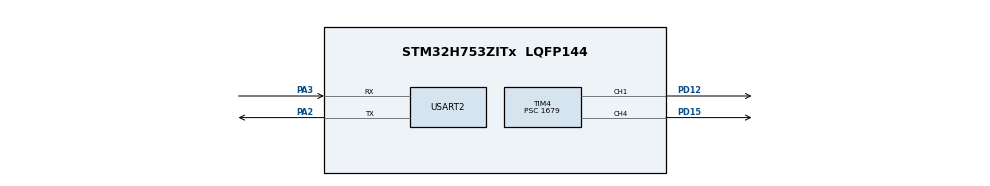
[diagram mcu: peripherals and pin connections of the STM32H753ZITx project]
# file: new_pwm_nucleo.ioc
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CORTEX_M7.CPU_DCache=Disabled
CORTEX_M7.CPU_ICache=Disabled
CORTEX_M7.MPU_Control=__NULL
CORTEX_M7.default_mode_Activation=1
Mcu.Family=STM32H7
Mcu.Name=STM32H753ZITx
Mcu.Package=LQFP144
NUCLEO-H753ZI.BUTTON=1
NUCLEO-H753ZI.Bsp_Common_DEMO=true
NUCLEO-H753ZI.LD1=true
NUCLEO-H753ZI.LD2=true
NUCLEO-H753ZI.LD3=true
NUCLEO-H753ZI.VCP=true
NVIC.EXTI15_10_IRQn=true\:0\:0\:false\:false\:true\:false\:true\:true
NVIC.PriorityGroup=NVIC_PRIORITYGROUP_4
PA2.Mode=Asynchronous
PA2.Signal=USART2_TX
PA3.Mode=Asynchronous
PA3.Signal=USART2_RX
PC14-OSC32_IN\ (OSC32_IN).Signal=RCC_OSC32_IN
PC15-OSC32_OUT\ (OSC32_OUT).Signal=RCC_OSC32_OUT
PD12.Signal=S_TIM4_CH1
PD15.Signal=S_TIM4_CH4
PD8.Signal=USART3_TX
PD9.Signal=USART3_RX
PH0-OSC_IN\ (PH0).Signal=RCC_OSC_IN
PH1-OSC_OUT\ (PH1).Signal=RCC_OSC_OUT
ProjectManager.HeapSize=0x200
ProjectManager.StackSize=0x400
ProjectManager.TargetToolchain=STM32CubeIDE
RCC.ADCFreq_Value=129000000
RCC.APB1Freq_Value=64000000
RCC.APB2Freq_Value=64000000
RCC.APB3Freq_Value=64000000
RCC.APB4Freq_Value=64000000
RCC.CortexFreq_Value=64000000
RCC.DIVM1=1
RCC.DIVN1=24
RCC.DIVQ1=4
RCC.HCLKFreq_Value=64000000
RCC.HSE_VALUE=8000000
RCC.PLLFRACN=0
RCC.PWR_Regulator_Voltage_Scale=PWR_REGULATOR_VOLTAGE_SCALE2
RCC.SYSCLKFreq_VALUE=64000000
RCC.USBFreq_Value=384000000
SH.S_TIM4_CH1.0=TIM4_CH1,PWM Generation1 CH1
SH.S_TIM4_CH4.0=TIM4_CH4,PWM Generation4 CH4
TIM4.AutoReloadPreload=TIM_AUTORELOAD_PRELOAD_ENABLE
TIM4.Channel-PWM\ Generation1\ CH1=TIM_CHANNEL_1
TIM4.Channel-PWM\ Generation4\ CH4=TIM_CHANNEL_4
TIM4.Period=999
TIM4.Prescaler=1679
USART2.VirtualMode-Asynchronous=VM_ASYNC
VP_MEMORYMAP_VS_MEMORYMAP.Mode=CurAppReg
VP_NUCLEO-H753ZI_VS_BSP_COMMON.Mode=COMMON
board=NUCLEO-H753ZI

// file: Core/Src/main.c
/* USER CODE BEGIN Header */
/**
  ******************************************************************************
  * @file           : main.c
  * @brief          : PWM Fade + UART Percentage Print (STM32F407G-DISC1)
  ******************************************************************************
  */
/* USER CODE END Header */

#include "main.h"
#include <stdio.h>
#include <string.h>

TIM_HandleTypeDef htim4;
UART_HandleTypeDef huart2;

void SystemClock_Config(void);
static void MX_GPIO_Init(void);
static void MX_TIM4_Init(void);
static void MX_USART2_UART_Init(void);

/* USER CODE BEGIN 0 */
static void UART_SendString(const char *s)
{
  HAL_UART_Transmit(&huart2, (uint8_t*)s, (uint16_t)strlen(s), HAL_MAX_DELAY);
}
/* USER CODE END 0 */

int main(void)
{
  HAL_Init();
  SystemClock_Config();

  MX_GPIO_Init();
  MX_TIM4_Init();
  MX_USART2_UART_Init();

  HAL_TIM_PWM_Start(&htim4, TIM_CHANNEL_1);

  UART_SendString("\r\n=== PWM Fade Started ===\r\n");

  uint32_t period = htim4.Init.Period;
  int last_printed_percent = -1;

  while (1)
  {
    /* Fade in */
    for (uint32_t duty = 0; duty <= period; duty += 2)
    {
      __HAL_TIM_SET_COMPARE(&htim4, TIM_CHANNEL_1, duty);

      int percent = (int)((duty * 100UL) / period);

      /* Print only each 5% change (reduce spam) */
      if (percent % 5 == 0 && percent != last_printed_percent)
      {
        char msg[64];
        snprintf(msg, sizeof(msg), "LED Brightness: %d%%\r\n", percent);
        UART_SendString(msg);
        last_printed_percent = percent;
      }

      HAL_Delay(5);
    }

    /* Fade out */
    for (int32_t duty = (int32_t)period; duty >= 0; duty -= 2)
    {
      __HAL_TIM_SET_COMPARE(&htim4, TIM_CHANNEL_1, (uint32_t)duty);

      int percent = (int)(((uint32_t)duty * 100UL) / period);

      if (percent % 5 == 0 && percent != last_printed_percent)
      {
        char msg[64];
        snprintf(msg, sizeof(msg), "LED Brightness: %d%%\r\n", percent);
        UART_SendString(msg);
        last_printed_percent = percent;
      }

      HAL_Delay(5);
    }
  }
}
